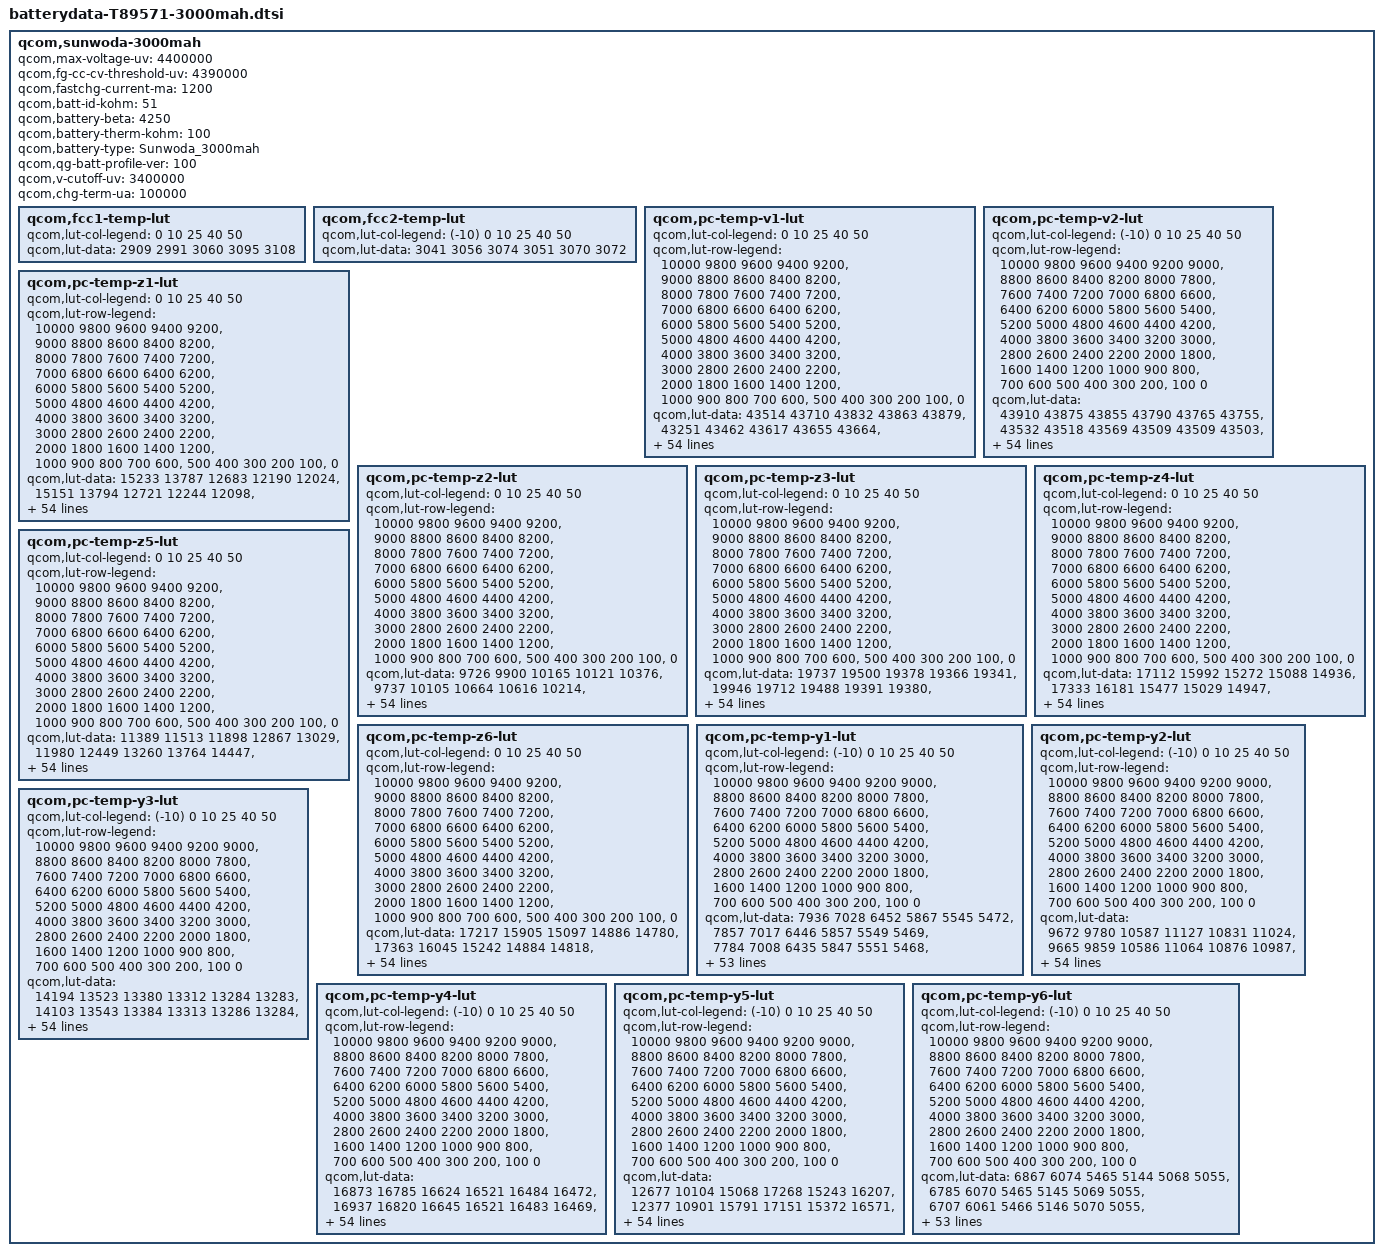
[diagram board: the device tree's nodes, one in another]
qcom,sunwoda-3000mah {
    /* 3689650_Wingtech_T89571_Sunwoda_3000mAH_averaged_MasterSlave_Nov22nd2018 */
    qcom,max-voltage-uv = <4400000>;
    qcom,fg-cc-cv-threshold-uv = <4390000>;
    qcom,fastchg-current-ma = <1200>; // default: 1500, the requirment is 1000
    qcom,batt-id-kohm = <51>;
    qcom,battery-beta = <4250>;
    qcom,battery-therm-kohm = <100>;
    qcom,battery-type = "Sunwoda_3000mah";
    qcom,qg-batt-profile-ver = <100>;
    qcom,v-cutoff-uv = <3400000>;
    qcom,chg-term-ua = <100000>;

    qcom,fcc1-temp-lut {
		qcom,lut-col-legend = <0 10 25 40 50>;
		qcom,lut-data = <2909 2991 3060 3095 3108>;
	};

	qcom,fcc2-temp-lut {
		qcom,lut-col-legend = <(-10) 0 10 25 40 50>;
		qcom,lut-data = <3041 3056 3074 3051 3070 3072>;
	};

	qcom,pc-temp-v1-lut {
		qcom,lut-col-legend = <0 10 25 40 50>;
		qcom,lut-row-legend = <10000 9800 9600 9400 9200>,
			<9000 8800 8600 8400 8200>,
			<8000 7800 7600 7400 7200>,
			<7000 6800 6600 6400 6200>,
			<6000 5800 5600 5400 5200>,
			<5000 4800 4600 4400 4200>,
			<4000 3800 3600 3400 3200>,
			<3000 2800 2600 2400 2200>,
			<2000 1800 1600 1400 1200>,
			<1000 900 800 700 600>,
			<500 400 300 200 100>,
			<0>;
		qcom,lut-data = <43514 43710 43832 43863 43879>,
			<43251 43462 43617 43655 43664>,
			<43003 43206 43374 43443 43458>,
			<42765 42960 43138 43213 43235>,
			<42536 42725 42903 42978 43002>,
			<42315 42492 42666 42740 42767>,
			<42100 42261 42430 42502 42530>,
			<41889 42035 42194 42265 42294>,
			<41684 41817 41962 42030 42061>,
			<41483 41604 41734 41798 41830>,
			<41292 41402 41509 41570 41600>,
			<41100 41222 41298 41347 41375>,
			<40891 41043 41112 41128 41155>,
			<40664 40821 40925 40915 40942>,
			<40429 40543 40695 40705 40733>,
			<40175 40285 40434 40498 40529>,
			<39937 40078 40218 40300 40333>,
			<39775 39902 40056 40122 40148>,
			<39660 39763 39906 39954 39971>,
			<39554 39651 39755 39787 39798>,
			<39436 39533 39602 39624 39636>,
			<39319 39398 39411 39443 39461>,
			<39204 39252 39150 39194 39228>,
			<39090 39082 38916 38942 38979>,
			<38981 38886 38760 38785 38811>,
			<38877 38716 38638 38673 38692>,
			<38776 38584 38542 38572 38585>,
			<38682 38476 38468 38477 38481>,
			<38595 38397 38400 38389 38384>,
			<38516 38334 38333 38304 38294>,
			<38449 38287 38271 38224 38211>,
			<38390 38253 38213 38155 38138>,
			<38338 38224 38158 38097 38075>,
			<38291 38195 38109 38042 38015>,
			<38248 38169 38068 37993 37958>,
			<38210 38140 38029 37947 37903>,
			<38176 38107 37990 37898 37845>,
			<38137 38068 37950 37849 37785>,
			<38080 38013 37896 37788 37715>,
			<38003 37927 37807 37703 37630>,
			<37910 37823 37698 37599 37529>,
			<37788 37701 37582 37483 37417>,
			<37651 37560 37450 37350 37288>,
			<37498 37399 37293 37198 37137>,
			<37349 37257 37152 37062 36999>,
			<37239 37169 37069 36977 36917>,
			<37200 37140 37042 36953 36897>,
			<37169 37114 37028 36940 36881>,
			<37141 37090 37010 36922 36862>,
			<37093 37047 36968 36868 36803>,
			<36894 36830 36733 36611 36540>,
			<36458 36397 36312 36177 36105>,
			<35890 35827 35748 35606 35537>,
			<35118 35053 34982 34828 34766>,
			<33903 33846 33802 33626 33581>,
			<30000 30000 30000 30000 30000>;
	};

	qcom,pc-temp-v2-lut {
		qcom,lut-col-legend = <(-10) 0 10 25 40 50>;
		qcom,lut-row-legend = <10000 9800 9600 9400 9200 9000>,
			<8800 8600 8400 8200 8000 7800>,
			<7600 7400 7200 7000 6800 6600>,
			<6400 6200 6000 5800 5600 5400>,
			<5200 5000 4800 4600 4400 4200>,
			<4000 3800 3600 3400 3200 3000>,
			<2800 2600 2400 2200 2000 1800>,
			<1600 1400 1200 1000 900 800>,
			<700 600 500 400 300 200>,
			<100 0>;
		qcom,lut-data = <43910 43875 43855 43790 43765 43755>,
			<43532 43518 43569 43509 43509 43503>,
			<43184 43196 43296 43242 43260 43257>,
			<42870 42912 43036 42989 43018 43018>,
			<42584 42664 42790 42750 42783 42785>,
			<42323 42423 42547 42515 42549 42552>,
			<42094 42175 42302 42280 42315 42319>,
			<41875 41937 42063 42048 42082 42086>,
			<41621 41727 41836 41821 41852 41857>,
			<41336 41536 41617 41598 41625 41629>,
			<41138 41343 41401 41377 41401 41404>,
			<41048 41142 41184 41155 41182 41184>,
			<40960 40936 40978 40940 40967 40967>,
			<40718 40727 40811 40750 40761 40759>,
			<40244 40511 40660 40575 40560 40555>,
			<39866 40248 40433 40380 40362 40359>,
			<39623 39877 40038 40144 40165 40167>,
			<39424 39547 39690 39917 39978 39983>,
			<39250 39377 39520 39752 39811 39813>,
			<39096 39254 39392 39613 39651 39646>,
			<38944 39111 39235 39434 39454 39447>,
			<38793 38940 39051 39177 39200 39205>,
			<38650 38775 38880 38935 38971 38984>,
			<38518 38629 38733 38770 38797 38809>,
			<38396 38493 38598 38633 38650 38657>,
			<38291 38364 38473 38510 38525 38529>,
			<38201 38236 38357 38400 38418 38419>,
			<38123 38134 38249 38300 38320 38319>,
			<38055 38064 38147 38208 38229 38227>,
			<37994 38007 38053 38123 38144 38142>,
			<37936 37954 37969 38048 38070 38065>,
			<37883 37905 37894 37978 38000 37993>,
			<37830 37858 37838 37914 37931 37925>,
			<37776 37814 37798 37854 37860 37863>,
			<37722 37770 37763 37797 37787 37797>,
			<37668 37724 37729 37738 37709 37703>,
			<37613 37676 37695 37675 37625 37590>,
			<37556 37622 37652 37612 37543 37488>,
			<37497 37557 37593 37548 37463 37399>,
			<37437 37484 37524 37480 37382 37314>,
			<37376 37398 37449 37398 37299 37234>,
			<37315 37300 37358 37300 37208 37148>,
			<37248 37206 37225 37184 37091 37030>,
			<37170 37119 37081 37050 36956 36898>,
			<37069 37034 36966 36923 36842 36786>,
			<36952 36951 36902 36874 36810 36759>,
			<36886 36914 36875 36861 36800 36747>,
			<36815 36869 36852 36845 36784 36731>,
			<36717 36801 36812 36816 36752 36702>,
			<36560 36671 36721 36733 36635 36584>,
			<36304 36396 36461 36464 36290 36240>,
			<35917 35981 35999 35989 35785 35742>,
			<35352 35401 35370 35380 35131 35096>,
			<34510 34568 34500 34567 34249 34239>,
			<33115 33315 33196 33280 32916 32984>,
			<28439 28179 28188 28991 28476 29013>;
	};

	qcom,pc-temp-z1-lut {
		qcom,lut-col-legend = <0 10 25 40 50>;
		qcom,lut-row-legend = <10000 9800 9600 9400 9200>,
			<9000 8800 8600 8400 8200>,
			<8000 7800 7600 7400 7200>,
			<7000 6800 6600 6400 6200>,
			<6000 5800 5600 5400 5200>,
			<5000 4800 4600 4400 4200>,
			<4000 3800 3600 3400 3200>,
			<3000 2800 2600 2400 2200>,
			<2000 1800 1600 1400 1200>,
			<1000 900 800 700 600>,
			<500 400 300 200 100>,
			<0>;
		qcom,lut-data = <15233 13787 12683 12190 12024>,
			<15151 13794 12721 12244 12098>,
			<15158 13826 12727 12247 12106>,
			<15181 13849 12730 12247 12106>,
			<15208 13864 12729 12246 12106>,
			<15252 13870 12722 12243 12106>,
			<15281 13868 12716 12239 12105>,
			<15264 13864 12709 12237 12106>,
			<15219 13858 12701 12235 12107>,
			<15193 13851 12703 12234 12108>,
			<15199 13847 12712 12233 12108>,
			<15209 13847 12719 12233 12108>,
			<15187 13841 12727 12235 12109>,
			<15119 13817 12733 12239 12111>,
			<15066 13775 12722 12239 12112>,
			<15042 13759 12688 12235 12112>,
			<15022 13764 12676 12231 12113>,
			<14991 13771 12685 12233 12114>,
			<14935 13778 12698 12238 12116>,
			<14893 13789 12712 12241 12117>,
			<14897 13802 12730 12244 12118>,
			<14928 13817 12740 12247 12119>,
			<14938 13834 12745 12250 12122>,
			<14926 13841 12750 12253 12125>,
			<14913 13845 12756 12257 12129>,
			<14923 13849 12762 12260 12133>,
			<14950 13860 12769 12264 12137>,
			<14956 13877 12776 12270 12143>,
			<14927 13882 12781 12276 12149>,
			<14902 13882 12783 12281 12153>,
			<14915 13883 12784 12287 12156>,
			<14958 13897 12788 12292 12160>,
			<14989 13920 12798 12298 12164>,
			<14984 13934 12809 12304 12167>,
			<14974 13941 12819 12309 12171>,
			<14980 13950 12829 12315 12176>,
			<15005 13967 12838 12320 12179>,
			<15021 13990 12848 12325 12182>,
			<15036 13999 12857 12331 12185>,
			<15072 14001 12868 12336 12189>,
			<15088 14007 12877 12341 12193>,
			<15091 14033 12883 12346 12198>,
			<15089 14057 12889 12350 12202>,
			<15081 14062 12900 12356 12205>,
			<15100 14056 12911 12365 12207>,
			<15060 14049 12901 12370 12212>,
			<15050 14053 12919 12369 12212>,
			<15053 14014 12920 12372 12214>,
			<15052 14036 12922 12375 12218>,
			<14996 14032 12922 12383 12222>,
			<15039 14064 12952 12390 12229>,
			<15096 14093 12958 12408 12239>,
			<15087 14090 12972 12419 12252>,
			<15131 14153 13014 12445 12271>,
			<15131 14153 13014 12445 12271>,
			<15131 14153 13014 12445 12271>;
	};

	qcom,pc-temp-z2-lut {
		qcom,lut-col-legend = <0 10 25 40 50>;
		qcom,lut-row-legend = <10000 9800 9600 9400 9200>,
			<9000 8800 8600 8400 8200>,
			<8000 7800 7600 7400 7200>,
			<7000 6800 6600 6400 6200>,
			<6000 5800 5600 5400 5200>,
			<5000 4800 4600 4400 4200>,
			<4000 3800 3600 3400 3200>,
			<3000 2800 2600 2400 2200>,
			<2000 1800 1600 1400 1200>,
			<1000 900 800 700 600>,
			<500 400 300 200 100>,
			<0>;
		qcom,lut-data = <9726 9900 10165 10121 10376>,
			<9737 10105 10664 10616 10214>,
			<9771 9978 10122 11243 11166>,
			<9812 9919 10117 11012 11069>,
			<9829 9894 10101 10702 10856>,
			<9832 9880 10063 10435 10602>,
			<9832 9872 10030 10199 10282>,
			<9825 9866 10009 10187 10165>,
			<9812 9872 9994 10370 10169>,
			<9801 9959 9995 10489 10173>,
			<9794 10035 10012 10482 10170>,
			<9787 9993 10048 10469 10164>,
			<9775 9896 10234 10473 10181>,
			<9756 9851 10446 10501 10358>,
			<9738 9835 10512 10531 10507>,
			<9719 9828 10548 10569 10559>,
			<9704 9836 10540 10596 10597>,
			<9702 9851 10325 10479 10537>,
			<9707 9866 10127 10207 10280>,
			<9712 9884 10125 10139 10172>,
			<9718 9899 10143 10211 10197>,
			<9725 9909 10154 10263 10219>,
			<9729 9918 10163 10260 10205>,
			<9732 9928 10168 10248 10182>,
			<9737 9944 10158 10221 10184>,
			<9742 9956 10141 10165 10215>,
			<9751 9959 10138 10146 10254>,
			<9760 9963 10145 10247 10324>,
			<9769 9967 10154 10350 10392>,
			<9778 9975 10170 10339 10366>,
			<9789 9983 10189 10300 10256>,
			<9801 9987 10195 10279 10197>,
			<9814 9991 10196 10256 10179>,
			<9834 9997 10197 10241 10171>,
			<9854 10006 10200 10251 10189>,
			<9833 10015 10206 10274 10231>,
			<9672 10025 10214 10302 10272>,
			<9534 10035 10231 10345 10332>,
			<9514 10047 10248 10384 10392>,
			<9506 10061 10271 10417 10455>,
			<9511 10075 10287 10440 10506>,
			<9529 10089 10284 10437 10490>,
			<9531 10106 10276 10425 10430>,
			<9457 10126 10287 10432 10406>,
			<9392 10264 10340 10441 10374>,
			<9383 10265 10419 10415 10301>,
			<9398 10310 10411 10391 10320>,
			<9403 10298 10454 10351 10332>,
			<9411 10343 10513 10386 10352>,
			<9458 10317 10560 10472 10440>,
			<9379 10301 10536 10462 10298>,
			<9350 10172 10630 10387 10160>,
			<9279 10073 10585 10262 10095>,
			<9240 9961 10496 10218 10044>,
			<9240 9961 10496 10218 10044>,
			<9240 9961 10496 10218 10044>;
	};

	qcom,pc-temp-z3-lut {
		qcom,lut-col-legend = <0 10 25 40 50>;
		qcom,lut-row-legend = <10000 9800 9600 9400 9200>,
			<9000 8800 8600 8400 8200>,
			<8000 7800 7600 7400 7200>,
			<7000 6800 6600 6400 6200>,
			<6000 5800 5600 5400 5200>,
			<5000 4800 4600 4400 4200>,
			<4000 3800 3600 3400 3200>,
			<3000 2800 2600 2400 2200>,
			<2000 1800 1600 1400 1200>,
			<1000 900 800 700 600>,
			<500 400 300 200 100>,
			<0>;
		qcom,lut-data = <19737 19500 19378 19366 19341>,
			<19946 19712 19488 19391 19380>,
			<20020 19811 19569 19434 19405>,
			<20059 19827 19597 19473 19441>,
			<20058 19829 19599 19495 19465>,
			<20005 19829 19595 19492 19467>,
			<19960 19827 19592 19484 19464>,
			<19956 19824 19591 19484 19459>,
			<19956 19824 19590 19497 19448>,
			<19957 19845 19584 19503 19439>,
			<19963 19861 19569 19490 19430>,
			<19970 19828 19562 19474 19419>,
			<19984 19769 19578 19467 19414>,
			<20023 19755 19596 19463 19414>,
			<20059 19775 19595 19459 19416>,
			<20081 19791 19588 19456 19415>,
			<20095 19776 19574 19451 19411>,
			<20079 19748 19528 19431 19402>,
			<20039 19724 19490 19398 19383>,
			<20008 19700 19491 19390 19372>,
			<19993 19688 19495 19395 19368>,
			<19982 19688 19502 19402 19366>,
			<19977 19692 19520 19409 19368>,
			<19974 19705 19532 19415 19371>,
			<19973 19736 19527 19410 19369>,
			<19974 19752 19515 19390 19353>,
			<19976 19751 19505 19382 19345>,
			<19976 19748 19495 19388 19370>,
			<19974 19745 19490 19397 19402>,
			<19969 19742 19496 19414 19412>,
			<19960 19737 19505 19441 19417>,
			<19941 19728 19512 19449 19418>,
			<19917 19715 19522 19442 19409>,
			<19892 19704 19526 19434 19397>,
			<19859 19693 19522 19425 19389>,
			<19789 19682 19515 19416 19382>,
			<19611 19668 19509 19411 19379>,
			<19465 19655 19504 19408 19378>,
			<19424 19647 19499 19406 19377>,
			<19399 19643 19494 19403 19378>,
			<19394 19637 19489 19402 19380>,
			<19396 19629 19485 19402 19378>,
			<19393 19617 19481 19402 19374>,
			<19342 19603 19477 19398 19372>,
			<19294 19557 19465 19386 19366>,
			<19278 19373 19434 19376 19357>,
			<19277 19331 19431 19376 19350>,
			<19276 19318 19392 19367 19344>,
			<19276 19313 19372 19364 19341>,
			<19273 19310 19363 19353 19337>,
			<19277 19325 19402 19355 19355>,
			<19279 19332 19360 19355 19364>,
			<19288 19332 19348 19365 19371>,
			<19301 19332 19346 19362 19371>,
			<19301 19332 19346 19362 19371>,
			<19301 19332 19346 19362 19371>;
	};

	qcom,pc-temp-z4-lut {
		qcom,lut-col-legend = <0 10 25 40 50>;
		qcom,lut-row-legend = <10000 9800 9600 9400 9200>,
			<9000 8800 8600 8400 8200>,
			<8000 7800 7600 7400 7200>,
			<7000 6800 6600 6400 6200>,
			<6000 5800 5600 5400 5200>,
			<5000 4800 4600 4400 4200>,
			<4000 3800 3600 3400 3200>,
			<3000 2800 2600 2400 2200>,
			<2000 1800 1600 1400 1200>,
			<1000 900 800 700 600>,
			<500 400 300 200 100>,
			<0>;
		qcom,lut-data = <17112 15992 15272 15088 14936>,
			<17333 16181 15477 15029 14947>,
			<17175 16085 15426 15108 15000>,
			<16833 15940 15267 15031 14955>,
			<16560 15732 15159 14956 14894>,
			<16362 15553 15081 14924 14865>,
			<16189 15429 15018 14900 14845>,
			<16033 15326 14963 14864 14827>,
			<15894 15225 14918 14803 14805>,
			<15775 15107 14885 14765 14787>,
			<15674 15025 14861 14759 14778>,
			<15584 15008 14831 14754 14772>,
			<15497 15004 14770 14745 14765>,
			<15409 14988 14720 14733 14741>,
			<15346 14951 14718 14722 14720>,
			<15316 14923 14724 14710 14706>,
			<15292 14910 14731 14703 14696>,
			<15261 14899 14746 14710 14694>,
			<15212 14881 14757 14729 14705>,
			<15160 14849 14751 14734 14713>,
			<15119 14826 14739 14728 14715>,
			<15082 14813 14747 14724 14719>,
			<15053 14804 14832 14799 14783>,
			<15031 14809 14911 14903 14887>,
			<15012 14846 14936 14925 14912>,
			<14990 14883 14952 14931 14916>,
			<14969 14910 14951 14932 14916>,
			<14957 14930 14931 14907 14874>,
			<14951 14930 14905 14868 14811>,
			<14946 14916 14874 14825 14775>,
			<14943 14899 14840 14776 14748>,
			<14944 14879 14813 14752 14733>,
			<14945 14856 14788 14740 14723>,
			<14948 14836 14772 14735 14719>,
			<14954 14817 14764 14736 14721>,
			<14993 14802 14759 14738 14727>,
			<15169 14789 14754 14741 14734>,
			<15304 14779 14750 14745 14742>,
			<15305 14773 14749 14750 14748>,
			<15297 14767 14758 14757 14752>,
			<15286 14763 14766 14764 14754>,
			<15253 14761 14760 14760 14752>,
			<15234 14759 14747 14748 14745>,
			<15236 14756 14742 14750 14747>,
			<15149 14750 14727 14745 14746>,
			<15114 14881 14699 14706 14710>,
			<15106 14917 14688 14689 14700>,
			<15099 14922 14714 14674 14678>,
			<15092 14919 14721 14654 14653>,
			<15082 14917 14728 14666 14657>,
			<15084 14915 14718 14705 14683>,
			<15120 14934 14777 14717 14684>,
			<15140 14950 14798 14711 14679>,
			<15170 14970 14810 14717 14681>,
			<15170 14970 14810 14717 14681>,
			<15170 14970 14810 14717 14681>;
	};

	qcom,pc-temp-z5-lut {
		qcom,lut-col-legend = <0 10 25 40 50>;
		qcom,lut-row-legend = <10000 9800 9600 9400 9200>,
			<9000 8800 8600 8400 8200>,
			<8000 7800 7600 7400 7200>,
			<7000 6800 6600 6400 6200>,
			<6000 5800 5600 5400 5200>,
			<5000 4800 4600 4400 4200>,
			<4000 3800 3600 3400 3200>,
			<3000 2800 2600 2400 2200>,
			<2000 1800 1600 1400 1200>,
			<1000 900 800 700 600>,
			<500 400 300 200 100>,
			<0>;
		qcom,lut-data = <11389 11513 11898 12867 13029>,
			<11980 12449 13260 13764 14447>,
			<12424 12999 14294 14025 14266>,
			<12768 13287 14706 14848 15289>,
			<12941 13472 14887 15501 16499>,
			<13016 13682 14976 15563 16813>,
			<13088 13960 15103 15587 16935>,
			<13233 14274 15467 16144 17035>,
			<13454 14728 15999 18760 17233>,
			<13658 15801 16421 20318 17449>,
			<13812 16675 16827 19972 17365>,
			<13951 16426 17573 19594 17018>,
			<14201 15708 20828 19822 17005>,
			<14899 15953 24089 20824 18305>,
			<15451 17671 24233 21914 19837>,
			<15769 18808 23694 23235 21213>,
			<16017 18243 22750 24094 22338>,
			<15928 17433 20062 22315 21866>,
			<15645 17328 17952 18196 19293>,
			<15517 17549 18943 17274 18278>,
			<15687 17925 22023 18995 18574>,
			<16041 19084 26183 20919 18864>,
			<16435 21532 33890 22630 19059>,
			<16893 26671 38908 23943 19207>,
			<17465 36804 35470 22809 18623>,
			<18315 42005 28465 18316 15698>,
			<19436 40657 24223 16013 14063>,
			<20380 38264 21226 15583 14640>,
			<21286 36556 19899 15362 15759>,
			<21933 35200 20119 16534 17181>,
			<21864 33747 20727 19832 19169>,
			<21254 31916 22067 22387 20761>,
			<20471 30077 25471 24373 21925>,
			<19509 28713 28238 25662 22872>,
			<18238 27648 30035 26270 23739>,
			<16519 26756 31273 26662 24430>,
			<13521 25611 31504 26667 24510>,
			<11409 24518 31450 26285 24236>,
			<11200 24538 31151 25724 23846>,
			<11111 25821 29593 23897 22889>,
			<11099 26687 27879 22003 21522>,
			<11183 25748 27093 21912 20538>,
			<11215 24424 26527 22097 19748>,
			<11087 23799 25689 20800 18908>,
			<11103 21862 25489 19625 18380>,
			<11081 12763 23046 20418 18677>,
			<11067 11852 22699 21483 18001>,
			<11059 11673 16549 20670 18663>,
			<11055 11598 14719 22793 21849>,
			<11058 11589 14252 19212 19713>,
			<11128 11881 16829 15566 17100>,
			<11130 11812 13405 14560 16941>,
			<11066 11690 12690 14827 17189>,
			<11043 11520 12400 14240 16323>,
			<11043 11520 12400 14240 16323>,
			<11043 11520 12400 14240 16323>;
	};

	qcom,pc-temp-z6-lut {
		qcom,lut-col-legend = <0 10 25 40 50>;
		qcom,lut-row-legend = <10000 9800 9600 9400 9200>,
			<9000 8800 8600 8400 8200>,
			<8000 7800 7600 7400 7200>,
			<7000 6800 6600 6400 6200>,
			<6000 5800 5600 5400 5200>,
			<5000 4800 4600 4400 4200>,
			<4000 3800 3600 3400 3200>,
			<3000 2800 2600 2400 2200>,
			<2000 1800 1600 1400 1200>,
			<1000 900 800 700 600>,
			<500 400 300 200 100>,
			<0>;
		qcom,lut-data = <17217 15905 15097 14886 14780>,
			<17363 16045 15242 14884 14818>,
			<17300 16047 15247 14937 14855>,
			<17146 16013 15199 14924 14851>,
			<17001 15904 15158 14909 14844>,
			<16866 15801 15118 14895 14835>,
			<16746 15734 15084 14879 14823>,
			<16656 15677 15059 14862 14811>,
			<16583 15629 15037 14845 14797>,
			<16521 15588 15017 14830 14784>,
			<16469 15551 15000 14818 14775>,
			<16421 15514 14985 14809 14767>,
			<16374 15478 14971 14801 14759>,
			<16330 15453 14960 14794 14750>,
			<16299 15435 14952 14787 14742>,
			<16279 15422 14946 14780 14735>,
			<16261 15409 14937 14773 14729>,
			<16232 15393 14921 14764 14722>,
			<16186 15376 14908 14755 14716>,
			<16143 15355 14908 14753 14714>,
			<16109 15345 14909 14754 14713>,
			<16081 15344 14916 14756 14713>,
			<16066 15346 14965 14793 14742>,
			<16059 15357 15005 14842 14790>,
			<16053 15390 15011 14847 14799>,
			<16045 15419 15015 14843 14795>,
			<16039 15434 15013 14837 14791>,
			<16038 15445 15002 14830 14785>,
			<16040 15445 14989 14821 14778>,
			<16041 15441 14980 14815 14770>,
			<16040 15435 14972 14808 14762>,
			<16036 15424 14967 14802 14755>,
			<16030 15412 14963 14795 14746>,
			<16023 15401 14959 14788 14739>,
			<16015 15392 14955 14784 14737>,
			<16006 15385 14952 14781 14735>,
			<15994 15378 14950 14780 14735>,
			<15985 15373 14947 14781 14738>,
			<15979 15372 14946 14782 14741>,
			<15974 15374 14950 14785 14744>,
			<15971 15376 14954 14788 14746>,
			<15970 15375 14952 14787 14744>,
			<15968 15374 14948 14783 14739>,
			<15955 15372 14946 14782 14740>,
			<15901 15348 14938 14776 14737>,
			<15878 15320 14914 14754 14717>,
			<15873 15316 14908 14747 14709>,
			<15869 15313 14900 14736 14697>,
			<15870 15311 14894 14726 14684>,
			<15871 15316 14896 14728 14685>,
			<15885 15332 14916 14747 14707>,
			<15915 15353 14926 14756 14715>,
			<15940 15375 14935 14761 14720>,
			<15986 15404 14950 14769 14725>,
			<15986 15404 14950 14769 14725>,
			<15986 15404 14950 14769 14725>;
	};

	qcom,pc-temp-y1-lut {
		qcom,lut-col-legend = <(-10) 0 10 25 40 50>;
		qcom,lut-row-legend = <10000 9800 9600 9400 9200 9000>,
			<8800 8600 8400 8200 8000 7800>,
			<7600 7400 7200 7000 6800 6600>,
			<6400 6200 6000 5800 5600 5400>,
			<5200 5000 4800 4600 4400 4200>,
			<4000 3800 3600 3400 3200 3000>,
			<2800 2600 2400 2200 2000 1800>,
			<1600 1400 1200 1000 900 800>,
			<700 600 500 400 300 200>,
			<100 0>;
		qcom,lut-data = <7936 7028 6452 5867 5545 5472>,
			<7857 7017 6446 5857 5549 5469>,
			<7784 7008 6435 5847 5551 5468>,
			<7726 7000 6424 5840 5552 5467>,
			<7687 6994 6416 5835 5553 5467>,
			<7674 6989 6413 5834 5553 5467>,
			<7694 6990 6418 5836 5552 5468>,
			<7721 6993 6424 5839 5551 5469>,
			<7721 6990 6420 5839 5550 5469>,
			<7706 6985 6407 5837 5549 5468>,
			<7700 6982 6402 5834 5549 5468>,
			<7742 6985 6403 5831 5549 5468>,
			<7792 6991 6405 5827 5548 5469>,
			<7791 7003 6402 5825 5548 5468>,
			<7763 7025 6394 5822 5546 5467>,
			<7748 7035 6394 5822 5546 5467>,
			<7724 7038 6407 5832 5548 5467>,
			<7703 7041 6418 5842 5549 5467>,
			<7706 7035 6420 5843 5549 5467>,
			<7716 7015 6421 5844 5548 5469>,
			<7723 7008 6422 5844 5549 5470>,
			<7725 7016 6428 5847 5551 5471>,
			<7727 7021 6431 5849 5553 5472>,
			<7733 7015 6427 5851 5555 5474>,
			<7743 7007 6422 5854 5556 5475>,
			<7752 7004 6419 5856 5558 5477>,
			<7761 7004 6415 5858 5561 5479>,
			<7764 7005 6414 5860 5563 5481>,
			<7754 7018 6420 5861 5565 5482>,
			<7738 7033 6425 5862 5568 5484>,
			<7734 7029 6427 5865 5571 5487>,
			<7734 7015 6431 5869 5575 5491>,
			<7733 7009 6434 5873 5579 5494>,
			<7721 7017 6441 5879 5582 5497>,
			<7707 7022 6446 5885 5586 5499>,
			<7705 7023 6442 5886 5589 5501>,
			<7705 7029 6436 5885 5593 5504>,
			<7706 7036 6435 5886 5596 5505>,
			<7741 7040 6432 5889 5597 5507>,
			<7790 7042 6429 5896 5599 5508>,
			<7790 7027 6428 5903 5601 5512>,
			<7745 7003 6428 5912 5605 5515>,
			<7722 7004 6434 5918 5610 5518>,
			<7761 7019 6469 5918 5615 5521>,
			<7778 7073 6488 5931 5623 5525>,
			<7863 7121 6476 5937 5627 5529>,
			<7858 7079 6482 5942 5630 5531>,
			<7862 7076 6507 5954 5630 5530>,
			<7817 7129 6503 5962 5631 5530>,
			<7893 7101 6494 5952 5631 5531>,
			<7876 7101 6490 5951 5636 5534>,
			<7885 7121 6508 5963 5644 5540>,
			<7976 7150 6558 5988 5656 5551>,
			<8122 7218 6580 6014 5677 5562>,
			<8122 7218 6580 6014 5677 5562>,
			<8122 7218 6580 6014 5677 5562>;
	};

	qcom,pc-temp-y2-lut {
		qcom,lut-col-legend = <(-10) 0 10 25 40 50>;
		qcom,lut-row-legend = <10000 9800 9600 9400 9200 9000>,
			<8800 8600 8400 8200 8000 7800>,
			<7600 7400 7200 7000 6800 6600>,
			<6400 6200 6000 5800 5600 5400>,
			<5200 5000 4800 4600 4400 4200>,
			<4000 3800 3600 3400 3200 3000>,
			<2800 2600 2400 2200 2000 1800>,
			<1600 1400 1200 1000 900 800>,
			<700 600 500 400 300 200>,
			<100 0>;
		qcom,lut-data = <9672 9780 10587 11127 10831 11024>,
			<9665 9859 10586 11064 10876 10987>,
			<9662 9946 10585 10997 10903 10920>,
			<9663 10031 10583 10934 10915 10846>,
			<9666 10101 10582 10881 10916 10788>,
			<9672 10144 10581 10846 10909 10768>,
			<9754 10166 10570 10826 10883 10770>,
			<9877 10183 10557 10810 10854 10775>,
			<9986 10201 10563 10794 10850 10780>,
			<10196 10229 10584 10776 10858 10789>,
			<10324 10274 10590 10770 10862 10793>,
			<10357 10476 10560 10783 10863 10792>,
			<10377 10671 10531 10805 10864 10793>,
			<10344 10636 10606 10831 10862 10806>,
			<10180 10516 10774 10869 10859 10831>,
			<10077 10476 10816 10886 10874 10860>,
			<9871 10511 10767 10884 10983 10893>,
			<9682 10562 10731 10884 11081 10937>,
			<9675 10611 10751 10923 11109 11031>,
			<9675 10662 10789 11006 11128 11143>,
			<9674 10687 10805 11030 11133 11155>,
			<9672 10700 10812 11005 11118 11096>,
			<9670 10705 10819 10984 11096 11043>,
			<9669 10701 10829 10989 11068 11016>,
			<9668 10690 10841 11001 11040 10999>,
			<9667 10583 10854 11010 11050 11001>,
			<9667 10090 10869 11022 11118 11023>,
			<9666 9765 10874 11032 11170 11060>,
			<9665 9728 10868 11040 11198 11160>,
			<9665 9708 10861 11048 11223 11259>,
			<9664 9703 10867 11057 11238 11279>,
			<9663 9702 10884 11069 11258 11282>,
			<9662 9701 10888 11075 11265 11293>,
			<9662 9691 10868 11070 11241 11320>,
			<9661 9679 10842 11063 11207 11336>,
			<9660 9675 10824 11059 11175 11291>,
			<9660 9671 10806 11049 11143 11189>,
			<9659 9669 10784 11041 11129 11100>,
			<9659 9666 10758 11026 11128 11009>,
			<9658 9664 10726 11007 11126 10961>,
			<9658 9662 10685 10986 11107 10989>,
			<9657 9660 10628 10955 11095 11025>,
			<9657 9659 10364 10935 11093 11006>,
			<9657 9658 9850 10905 11053 10964>,
			<9656 9658 9789 10854 10949 10892>,
			<9656 9657 9697 10828 10892 10786>,
			<9655 9656 9682 10817 10896 10762>,
			<9655 9656 9674 10803 10910 10763>,
			<9655 9655 9670 10796 10911 10830>,
			<9655 9655 9666 10778 10906 10827>,
			<9654 9655 9664 10757 10863 10761>,
			<9654 9654 9660 10680 10820 10698>,
			<9654 9654 9657 10603 10772 10682>,
			<9652 9653 9655 10544 10708 10610>,
			<9652 9653 9655 10544 10708 10610>,
			<9652 9653 9655 10544 10708 10610>;
	};

	qcom,pc-temp-y3-lut {
		qcom,lut-col-legend = <(-10) 0 10 25 40 50>;
		qcom,lut-row-legend = <10000 9800 9600 9400 9200 9000>,
			<8800 8600 8400 8200 8000 7800>,
			<7600 7400 7200 7000 6800 6600>,
			<6400 6200 6000 5800 5600 5400>,
			<5200 5000 4800 4600 4400 4200>,
			<4000 3800 3600 3400 3200 3000>,
			<2800 2600 2400 2200 2000 1800>,
			<1600 1400 1200 1000 900 800>,
			<700 600 500 400 300 200>,
			<100 0>;
		qcom,lut-data = <14194 13523 13380 13312 13284 13283>,
			<14103 13543 13384 13313 13286 13284>,
			<14015 13555 13390 13315 13288 13285>,
			<13932 13559 13396 13316 13290 13287>,
			<13857 13560 13401 13317 13292 13288>,
			<13791 13557 13403 13318 13294 13290>,
			<13731 13545 13404 13319 13296 13292>,
			<13680 13531 13405 13320 13298 13294>,
			<13642 13536 13405 13321 13299 13295>,
			<13608 13560 13404 13324 13300 13297>,
			<13576 13569 13404 13325 13302 13298>,
			<13532 13509 13410 13324 13307 13298>,
			<13497 13444 13415 13324 13311 13299>,
			<13502 13441 13409 13325 13311 13302>,
			<13524 13444 13394 13328 13311 13307>,
			<13534 13445 13385 13329 13310 13308>,
			<13527 13432 13381 13328 13309 13307>,
			<13517 13421 13379 13327 13308 13305>,
			<13513 13421 13377 13329 13306 13302>,
			<13509 13422 13376 13331 13304 13299>,
			<13507 13422 13373 13331 13302 13296>,
			<13507 13413 13367 13323 13299 13291>,
			<13506 13405 13363 13315 13295 13287>,
			<13496 13401 13360 13312 13291 13284>,
			<13479 13398 13358 13311 13288 13283>,
			<13474 13386 13356 13310 13288 13282>,
			<13475 13351 13353 13309 13289 13282>,
			<13476 13328 13350 13308 13290 13283>,
			<13482 13318 13349 13309 13289 13283>,
			<13495 13310 13347 13310 13289 13284>,
			<13510 13320 13342 13310 13290 13284>,
			<13533 13361 13332 13311 13293 13283>,
			<13561 13385 13330 13312 13294 13282>,
			<13591 13389 13335 13313 13293 13285>,
			<13624 13392 13343 13314 13291 13287>,
			<13660 13401 13349 13314 13291 13286>,
			<13702 13422 13356 13312 13290 13284>,
			<13748 13447 13359 13311 13290 13283>,
			<13798 13479 13361 13312 13291 13282>,
			<13853 13517 13363 13312 13291 13282>,
			<13912 13558 13365 13312 13292 13284>,
			<13974 13604 13367 13312 13292 13287>,
			<14039 13654 13367 13313 13293 13286>,
			<14102 13714 13371 13314 13290 13283>,
			<14110 13695 13365 13311 13288 13282>,
			<14122 13750 13398 13312 13293 13292>,
			<14197 13808 13412 13317 13298 13294>,
			<14268 13858 13428 13323 13304 13297>,
			<14332 13920 13453 13329 13311 13303>,
			<14399 13978 13483 13335 13308 13300>,
			<14472 14025 13513 13333 13300 13293>,
			<14569 14091 13584 13333 13305 13295>,
			<14675 14168 13707 13346 13312 13302>,
			<15208 14288 13866 13363 13319 13309>,
			<15208 14288 13866 13363 13319 13309>,
			<15208 14288 13866 13363 13319 13309>;
	};

	qcom,pc-temp-y4-lut {
		qcom,lut-col-legend = <(-10) 0 10 25 40 50>;
		qcom,lut-row-legend = <10000 9800 9600 9400 9200 9000>,
			<8800 8600 8400 8200 8000 7800>,
			<7600 7400 7200 7000 6800 6600>,
			<6400 6200 6000 5800 5600 5400>,
			<5200 5000 4800 4600 4400 4200>,
			<4000 3800 3600 3400 3200 3000>,
			<2800 2600 2400 2200 2000 1800>,
			<1600 1400 1200 1000 900 800>,
			<700 600 500 400 300 200>,
			<100 0>;
		qcom,lut-data = <16873 16785 16624 16521 16484 16472>,
			<16937 16820 16645 16521 16483 16469>,
			<17003 16858 16674 16523 16482 16467>,
			<17062 16893 16703 16525 16481 16466>,
			<17104 16922 16727 16529 16481 16466>,
			<17122 16942 16739 16532 16481 16465>,
			<17118 16957 16742 16537 16483 16466>,
			<17105 16967 16745 16542 16487 16468>,
			<17081 16960 16757 16549 16492 16470>,
			<17027 16932 16782 16557 16498 16474>,
			<17007 16926 16794 16566 16503 16479>,
			<17239 17080 16793 16577 16506 16487>,
			<17511 17247 16793 16593 16508 16495>,
			<17429 17246 16868 16620 16518 16500>,
			<17088 17198 17030 16662 16537 16503>,
			<16928 17118 17051 16682 16556 16509>,
			<16913 16894 16828 16688 16576 16524>,
			<16905 16716 16655 16692 16598 16546>,
			<16901 16722 16666 16697 16630 16578>,
			<16897 16744 16689 16702 16663 16613>,
			<16891 16747 16687 16693 16657 16613>,
			<16867 16718 16651 16607 16580 16563>,
			<16847 16684 16620 16530 16517 16517>,
			<16845 16654 16606 16516 16497 16494>,
			<16848 16629 16595 16508 16486 16480>,
			<16852 16634 16586 16507 16486 16479>,
			<16859 16684 16580 16511 16491 16484>,
			<16864 16722 16572 16515 16498 16491>,
			<16862 16740 16560 16520 16509 16500>,
			<16859 16755 16550 16526 16524 16512>,
			<16858 16750 16552 16533 16536 16526>,
			<16856 16722 16561 16542 16547 16544>,
			<16853 16708 16566 16548 16552 16556>,
			<16854 16718 16567 16550 16553 16563>,
			<16858 16731 16567 16552 16553 16567>,
			<16864 16740 16574 16549 16545 16551>,
			<16872 16746 16587 16539 16524 16514>,
			<16883 16749 16599 16533 16508 16496>,
			<16897 16749 16612 16531 16497 16489>,
			<16914 16748 16624 16530 16492 16486>,
			<16934 16744 16636 16530 16497 16490>,
			<16962 16739 16644 16532 16502 16495>,
			<16982 16740 16643 16531 16499 16493>,
			<16991 16740 16654 16527 16490 16482>,
			<16936 16732 16630 16501 16464 16459>,
			<16871 16739 16648 16511 16481 16468>,
			<16887 16760 16675 16529 16497 16490>,
			<16904 16789 16706 16554 16518 16516>,
			<16928 16826 16748 16588 16546 16548>,
			<16921 16837 16782 16605 16547 16541>,
			<16907 16825 16766 16578 16497 16484>,
			<16902 16833 16752 16561 16490 16478>,
			<16920 16860 16768 16585 16505 16488>,
			<17157 16915 16825 16643 16579 16557>,
			<17157 16915 16825 16643 16579 16557>,
			<17157 16915 16825 16643 16579 16557>;
	};

	qcom,pc-temp-y5-lut {
		qcom,lut-col-legend = <(-10) 0 10 25 40 50>;
		qcom,lut-row-legend = <10000 9800 9600 9400 9200 9000>,
			<8800 8600 8400 8200 8000 7800>,
			<7600 7400 7200 7000 6800 6600>,
			<6400 6200 6000 5800 5600 5400>,
			<5200 5000 4800 4600 4400 4200>,
			<4000 3800 3600 3400 3200 3000>,
			<2800 2600 2400 2200 2000 1800>,
			<1600 1400 1200 1000 900 800>,
			<700 600 500 400 300 200>,
			<100 0>;
		qcom,lut-data = <12677 10104 15068 17268 15243 16207>,
			<12377 10901 15791 17151 15372 16571>,
			<12315 12297 16235 16930 15449 16809>,
			<12438 13833 16470 16630 15488 16947>,
			<12692 15048 16562 16277 15501 17010>,
			<13029 15484 16573 15893 15500 17021>,
			<13879 15395 16365 15412 15349 16921>,
			<14780 15282 16039 14917 15074 16725>,
			<14709 16201 15795 14567 14740 16471>,
			<13918 19408 15540 14298 14308 16095>,
			<13655 20725 15300 14005 14177 15659>,
			<14380 17131 15035 13528 14622 14986>,
			<15380 13251 14865 13093 15068 14487>,
			<16633 14879 15013 12938 14734 14673>,
			<18725 20066 15533 12846 13820 15161>,
			<18985 21791 16386 12869 13319 15214>,
			<15761 19265 18439 13779 13077 14309>,
			<12839 16936 19977 15319 12964 13511>,
			<12768 17700 20348 17747 13328 13361>,
			<12895 19627 20591 20930 14316 13280>,
			<12949 20401 20601 21752 15680 13659>,
			<12951 20316 20437 20924 18036 15783>,
			<12912 20239 20329 20059 19309 17106>,
			<12666 20498 20486 19586 18258 16820>,
			<12166 20755 20678 19102 16662 16283>,
			<11836 19868 20605 18706 16294 15763>,
			<11623 14991 20320 18303 16349 15167>,
			<11516 11870 20114 18022 16420 14881>,
			<11524 11656 19908 18095 16230 14835>,
			<11543 11543 19547 18485 15965 14801>,
			<11560 11658 18195 18946 16373 14717>,
			<11647 12161 15419 19640 17691 14604>,
			<11731 12457 14523 20399 18198 14685>,
			<11774 12509 15514 21406 17959 15928>,
			<11824 12549 16864 22249 17776 17211>,
			<11867 12692 18250 22071 18117 17668>,
			<11934 13006 19630 20900 18711 17988>,
			<11989 13272 19880 19933 18777 17931>,
			<12047 13502 19309 19369 18456 16830>,
			<12125 13652 18730 18842 18095 15967>,
			<12236 13463 18426 18173 17482 16308>,
			<12436 12991 18237 17238 16850 16730>,
			<12664 12765 16548 16964 17064 16402>,
			<12941 12842 13712 16910 16593 16102>,
			<13093 12736 13049 16858 17160 16393>,
			<13216 13032 13306 15879 15402 16725>,
			<13358 13182 13025 15736 15332 15279>,
			<13775 13240 13160 15373 15348 15040>,
			<13746 13345 13108 15095 16163 15752>,
			<14061 13823 13341 15859 15868 15341>,
			<13990 13965 13449 16601 15973 15728>,
			<13864 14012 13399 16740 18591 17067>,
			<13552 13821 13556 18511 21867 20578>,
			<12211 13769 13773 20503 23500 24215>,
			<12211 13769 13773 20503 23500 24215>,
			<12211 13769 13773 20503 23500 24215>;
	};

	qcom,pc-temp-y6-lut {
		qcom,lut-col-legend = <(-10) 0 10 25 40 50>;
		qcom,lut-row-legend = <10000 9800 9600 9400 9200 9000>,
			<8800 8600 8400 8200 8000 7800>,
			<7600 7400 7200 7000 6800 6600>,
			<6400 6200 6000 5800 5600 5400>,
			<5200 5000 4800 4600 4400 4200>,
			<4000 3800 3600 3400 3200 3000>,
			<2800 2600 2400 2200 2000 1800>,
			<1600 1400 1200 1000 900 800>,
			<700 600 500 400 300 200>,
			<100 0>;
		qcom,lut-data = <6867 6074 5465 5144 5068 5055>,
			<6785 6070 5465 5145 5069 5055>,
			<6707 6061 5466 5146 5070 5055>,
			<6635 6047 5466 5147 5072 5056>,
			<6571 6029 5465 5148 5074 5058>,
			<6516 6008 5465 5150 5075 5059>,
			<6473 5979 5460 5151 5077 5061>,
			<6434 5951 5453 5153 5080 5062>,
			<6390 5933 5451 5155 5082 5065>,
			<6342 5919 5450 5158 5084 5067>,
			<6323 5908 5450 5161 5087 5069>,
			<6349 5899 5447 5164 5091 5072>,
			<6379 5890 5446 5167 5094 5075>,
			<6355 5881 5459 5175 5099 5078>,
			<6266 5871 5489 5188 5103 5081>,
			<6215 5853 5490 5195 5108 5085>,
			<6201 5795 5428 5197 5113 5089>,
			<6193 5748 5380 5199 5118 5093>,
			<6193 5749 5383 5201 5126 5100>,
			<6194 5755 5387 5203 5133 5107>,
			<6194 5755 5385 5201 5130 5106>,
			<6193 5743 5371 5170 5106 5087>,
			<6191 5731 5360 5143 5084 5071>,
			<6192 5727 5355 5138 5076 5062>,
			<6195 5723 5352 5135 5071 5057>,
			<6200 5722 5352 5135 5071 5057>,
			<6209 5722 5351 5136 5073 5058>,
			<6221 5724 5351 5137 5076 5060>,
			<6231 5732 5352 5140 5080 5064>,
			<6241 5746 5352 5143 5084 5068>,
			<6256 5761 5354 5147 5089 5072>,
			<6277 5777 5356 5151 5094 5076>,
			<6302 5796 5361 5155 5096 5080>,
			<6329 5821 5372 5158 5096 5084>,
			<6360 5851 5387 5160 5096 5087>,
			<6394 5884 5403 5160 5093 5082>,
			<6433 5922 5422 5158 5087 5070>,
			<6476 5963 5443 5156 5083 5064>,
			<6522 6008 5467 5157 5081 5062>,
			<6572 6057 5495 5160 5080 5061>,
			<6627 6108 5530 5162 5082 5065>,
			<6687 6162 5569 5166 5085 5068>,
			<6749 6215 5607 5170 5084 5067>,
			<6808 6275 5646 5172 5081 5063>,
			<6823 6274 5626 5168 5073 5056>,
			<6840 6333 5694 5174 5082 5066>,
			<6906 6387 5742 5187 5091 5074>,
			<6969 6439 5799 5202 5101 5084>,
			<7027 6504 5861 5219 5114 5098>,
			<7090 6557 5926 5231 5112 5093>,
			<7152 6597 5969 5225 5093 5072>,
			<7239 6663 6061 5228 5096 5073>,
			<7358 6741 6218 5260 5108 5082>,
			<7968 6869 6394 5304 5137 5109>,
			<7968 6869 6394 5304 5137 5109>,
			<7968 6869 6394 5304 5137 5109>;
	};

};
